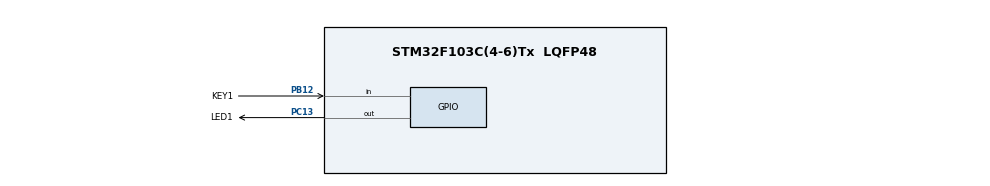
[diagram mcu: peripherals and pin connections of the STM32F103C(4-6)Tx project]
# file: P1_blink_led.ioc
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Mcu.Family=STM32F1
Mcu.Name=STM32F103C(4-6)Tx
Mcu.Package=LQFP48
NVIC.PriorityGroup=NVIC_PRIORITYGROUP_4
PA13.Mode=Serial_Wire
PA13.Signal=SYS_JTMS-SWDIO
PA14.Mode=Serial_Wire
PA14.Signal=SYS_JTCK-SWCLK
PB12.GPIO_Label=KEY1
PB12.GPIO_PuPd=GPIO_PULLUP
PB12.Signal=GPIO_Input
PC13-TAMPER-RTC.GPIO_Label=LED1
PC13-TAMPER-RTC.Signal=GPIO_Output
ProjectManager.HeapSize=0x200
ProjectManager.StackSize=0x400
ProjectManager.TargetToolchain=MDK-ARM V5.32
RCC.APB1Freq_Value=8000000
RCC.APB2Freq_Value=8000000
board=custom

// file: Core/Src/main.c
/* USER CODE BEGIN Header */
/**
  ******************************************************************************
  * @file           : main.c
  * @brief          : Main program body
  ******************************************************************************
  * @attention
  *
  * Copyright (c) 2026 STMicroelectronics.
  * All rights reserved.
  *
  * This software is licensed under terms that can be found in the LICENSE file
  * in the root directory of this software component.
  * If no LICENSE file comes with this software, it is provided AS-IS.
  *
  ******************************************************************************
  */
/* USER CODE END Header */
#include "main.h"

/* USER CODE BEGIN PD */

#define LED1(x) ((x==1) ? (HAL_GPIO_WritePin(LED1_GPIO_Port,LED1_Pin,GPIO_PIN_RESET)) : (HAL_GPIO_WritePin(LED1_GPIO_Port,LED1_Pin,GPIO_PIN_SET)))
#define KEY1 (HAL_GPIO_ReadPin(KEY1_GPIO_Port,KEY1_Pin))
/* USER CODE END PD */

void SystemClock_Config(void);
static void MX_GPIO_Init(void);

int main(void)
{

  /* MCU Configuration--------------------------------------------------------*/

  /* Reset of all peripherals, Initializes the Flash interface and the Systick. */
  HAL_Init();

  /* USER CODE BEGIN Init */
	HAL_Delay(1000);

  /* USER CODE END Init */

  /* Configure the system clock */
  SystemClock_Config();

  /* Initialize all configured peripherals */
  MX_GPIO_Init();
  /* USER CODE BEGIN 2 */
	LED1(0);

  /* USER CODE END 2 */

  /* Infinite loop */
  while (1)
  {

    /* USER CODE BEGIN 3 */
		static uint8_t led_state = 0;

		// 1. Check if Button is pressed (KEY1 returns 0/GPIO_PIN_RESET when pressed)
    if (KEY1 == GPIO_PIN_RESET)
    {
        HAL_Delay(20); // Debounce: wait 20ms to ignore noise

        // Check again to confirm it's a real press
        if (KEY1 == GPIO_PIN_RESET)
        {
            uint32_t start_time = HAL_GetTick();
					  uint8_t  long_press = 0;

					 // 2. Wait while the button is held down
            while (KEY1 == GPIO_PIN_RESET)
            {

							if (!long_press && (HAL_GetTick() - start_time >= 3000))
            {
                long_press = 1;
                led_state  = 1;
                LED1(led_state);         // Immediate feedback at 3 s
            }

					}
						   // 3. Handle Short Press
            // If the button was released BEFORE 3 seconds passed

					   // 4. Decide action based on duration
					 // 3. Calculate how long the button was held
             HAL_Delay(50);                   // Release debounce

          if (long_press)
            {
                // Long Press: Turn LED ON and keep it ON
                LED1(1);
            }
            else
            {
                LED1(1);       // Turn LED ON
                HAL_Delay(1000); // Wait 1 second
                LED1(led_state ? 1 : 0);     // Restore previous state
            }
        }
    }

		        HAL_Delay(10); // Small delay to save CPU when button is not pressed

  }
  /* USER CODE END 3 */
}

void SystemClock_Config(void)
{
  RCC_OscInitTypeDef RCC_OscInitStruct = {0};
  RCC_ClkInitTypeDef RCC_ClkInitStruct = {0};

  /** Initializes the RCC Oscillators according to the specified parameters
  * in the RCC_OscInitTypeDef structure.
  */
  RCC_OscInitStruct.OscillatorType = RCC_OSCILLATORTYPE_HSI;
  RCC_OscInitStruct.HSIState = RCC_HSI_ON;
  RCC_OscInitStruct.HSICalibrationValue = RCC_HSICALIBRATION_DEFAULT;
  RCC_OscInitStruct.PLL.PLLState = RCC_PLL_NONE;
  if (HAL_RCC_OscConfig(&RCC_OscInitStruct) != HAL_OK)
  {
    Error_Handler();
  }

  /** Initializes the CPU, AHB and APB buses clocks
  */
  RCC_ClkInitStruct.ClockType = RCC_CLOCKTYPE_HCLK|RCC_CLOCKTYPE_SYSCLK
                              |RCC_CLOCKTYPE_PCLK1|RCC_CLOCKTYPE_PCLK2;
  RCC_ClkInitStruct.SYSCLKSource = RCC_SYSCLKSOURCE_HSI;
  RCC_ClkInitStruct.AHBCLKDivider = RCC_SYSCLK_DIV1;
  RCC_ClkInitStruct.APB1CLKDivider = RCC_HCLK_DIV1;
  RCC_ClkInitStruct.APB2CLKDivider = RCC_HCLK_DIV1;

  if (HAL_RCC_ClockConfig(&RCC_ClkInitStruct, FLASH_LATENCY_0) != HAL_OK)
  {
    Error_Handler();
  }
}

static void MX_GPIO_Init(void)
{
  GPIO_InitTypeDef GPIO_InitStruct = {0};

  /* GPIO Ports Clock Enable */
  __HAL_RCC_GPIOC_CLK_ENABLE();
  __HAL_RCC_GPIOB_CLK_ENABLE();
  __HAL_RCC_GPIOA_CLK_ENABLE();

  /*Configure GPIO pin Output Level */
  HAL_GPIO_WritePin(LED1_GPIO_Port, LED1_Pin, GPIO_PIN_RESET);

  /*Configure GPIO pin : LED1_Pin */
  GPIO_InitStruct.Pin = LED1_Pin;
  GPIO_InitStruct.Mode = GPIO_MODE_OUTPUT_PP;
  GPIO_InitStruct.Pull = GPIO_NOPULL;
  GPIO_InitStruct.Speed = GPIO_SPEED_FREQ_LOW;
  HAL_GPIO_Init(LED1_GPIO_Port, &GPIO_InitStruct);

  /*Configure GPIO pin : KEY1_Pin */
  GPIO_InitStruct.Pin = KEY1_Pin;
  GPIO_InitStruct.Mode = GPIO_MODE_INPUT;
  GPIO_InitStruct.Pull = GPIO_PULLUP;
  HAL_GPIO_Init(KEY1_GPIO_Port, &GPIO_InitStruct);

}

void Error_Handler(void)
{
  __disable_irq();
  while (1)
  {
  }
}
